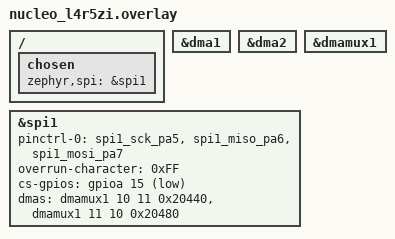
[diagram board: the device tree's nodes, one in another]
/*
 * Copyright (c) 2025 Waqar Ahmed
 * SPDX-License-Identifier: Apache-2.0
 */

/ {
	chosen {
		zephyr,spi = &spi1;
	};
};

&dma1 {
	status = "okay";
};

&dma2 {
	status = "okay";
};

&dmamux1 {
	status = "okay";
};

spi_master: &spi1 {
	status = "okay";
	/* SPI1 default pins */
	pinctrl-0 = <&spi1_sck_pa5 &spi1_miso_pa6 &spi1_mosi_pa7>;
	pinctrl-names = "default";
	overrun-character = <0xFF>;
	cs-gpios = <&gpioa 15 GPIO_ACTIVE_LOW>;
	dmas = <&dmamux1 10 11 0x20440>,   /* SPI1_TX: slot 10, request 11, M2P+MINC */
	       <&dmamux1 11 10 0x20480>;   /* SPI1_RX: slot 11, request 10, P2M+MINC */
	dma-names = "tx", "rx";
};
